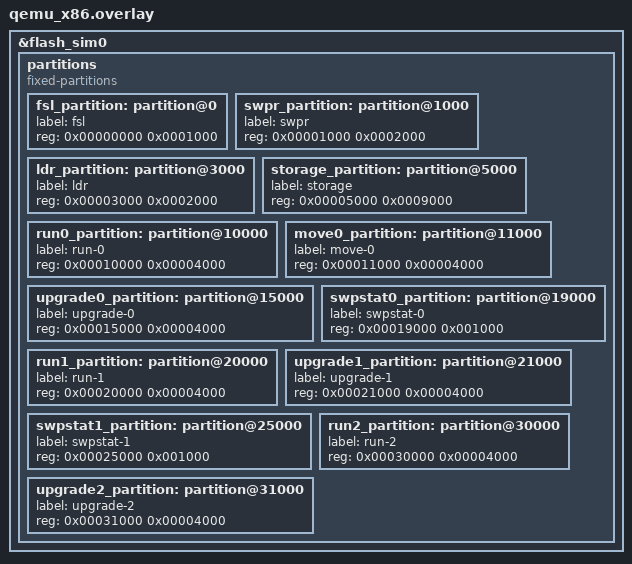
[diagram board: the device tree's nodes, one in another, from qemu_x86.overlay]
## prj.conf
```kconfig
CONFIG_ZTEST=y
CONFIG_ZTEST_STACKSIZE=8120
CONFIG_MAIN_STACK_SIZE=4096
CONFIG_FLASH=y
CONFIG_FLASH_PAGE_LAYOUT=y
#CONFIG_FLASH_SIMULATOR_DOUBLE_WRITES=y
CONFIG_FLASH_MAP=y
CONFIG_ZB_EIGHT=y
CONFIG_ZB_EIGHT_IS_SWAPPER=y

CONFIG_LOG=y
CONFIG_LOG_MINIMAL=y
```

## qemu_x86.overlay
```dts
/*
 * Copyright (c) 2019 Laczen
 *
 * SPDX-License-Identifier: Apache-2.0
 */

/delete-node/ &storage_partition;

&flash_sim0 {
	/*
	 * For more information, see:
	 * http://docs.zephyrproject.org/latest/guides/dts/index.html#flash-partitions
	 */
	partitions {
		compatible = "fixed-partitions";
		#address-cells = <1>;
		#size-cells = <1>;

		fsl_partition: partition@0 {
			label = "fsl";
			reg = <0x00000000 0x0001000>;
		};

		swpr_partition: partition@1000 {
			label = "swpr";
			reg = <0x00001000 0x0002000>;
		};

		ldr_partition: partition@3000 {
			label = "ldr";
			reg = <0x00003000 0x0002000>;
		};

		storage_partition: partition@5000 {
			label = "storage";
			reg = <0x00005000 0x0009000>;
		};

		run0_partition: partition@10000 {
			label = "run-0";
			reg = <0x00010000 0x00004000>;
		};
		move0_partition: partition@11000 {
			label = "move-0";
			reg = <0x00011000 0x00004000>;
		};
		upgrade0_partition: partition@15000 {
			label = "upgrade-0";
			reg = <0x00015000 0x00004000>;
		};
		swpstat0_partition: partition@19000 {
			label = "swpstat-0";
			reg = <0x00019000 0x001000>;
		};

		run1_partition: partition@20000 {
			label = "run-1";
			reg = <0x00020000 0x00004000>;
		};
		upgrade1_partition: partition@21000 {
			label = "upgrade-1";
			reg = <0x00021000 0x00004000>;
		};
		swpstat1_partition: partition@25000 {
			label = "swpstat-1";
			reg = <0x00025000 0x001000>;
		};

		run2_partition: partition@30000 {
			label = "run-2";
			reg = <0x00030000 0x00004000>;
		};
		upgrade2_partition: partition@31000 {
			label = "upgrade-2";
			reg = <0x00031000 0x00004000>;
		};
	};
};
```

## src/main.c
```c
/*
 * Copyright (c) 2017 Nordic Semiconductor ASA
 * Copyright (c) 2015 Runtime Inc
 *
 * SPDX-License-Identifier: Apache-2.0
 */

#include <logging/log.h>
LOG_MODULE_REGISTER(main);

extern void test_zb_flash(void);
extern void test_zb_tlv(void);
extern void test_zb_crypto(void);
extern void test_zb_image(void);
extern void test_zb_move(void);

void test_main(void)
{
	test_zb_flash();
	test_zb_tlv();
	test_zb_crypto();
	test_zb_image();
	test_zb_move();
}
```

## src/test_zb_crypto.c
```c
/*
 * Copyright (c) 2019 Laczen
 * Copyright (c) 2017 Nordic Semiconductor ASA
 * Copyright (c) 2015 Runtime Inc
 *
 * SPDX-License-Identifier: Apache-2.0
 */

#include <ztest.h>

#include <zb8/zb8_flash.h>
#include <zb8/zb8_crypto.h>

#include <logging/log.h>
LOG_MODULE_REGISTER(test_zb_crypto);

extern u8_t test_msg[];
extern u8_t test_msg_hash[];

/**
 * @brief Test hash calculation for data in flash
 */
void test_zb_hash(void)
{
	int err, cnt;
	struct zb_slt_info info;
	u8_t hash[HASH_BYTES];

	cnt = zb_slt_area_cnt();
	zassert_false(cnt == 0,  "Unable to get slotarea count: [cnt %d]", cnt);

	err = zb_slt_open(&info, cnt - 1, RUN);
	zassert_true(err == 0,  "Unable to get info: [err %d]", err);

	err = zb_erase(&info, 0, info.size);
	zassert_true(err == 0,  "Unable to erase image 0 area: [err %d]", err);

	err = zb_write(&info, 0, test_msg, HASH_BYTES);
	zassert_true(err == 0,  "Unable to write test message: [err %d]", err);


	err = zb_hash(hash, &info, 0, HASH_BYTES);
	zassert_true(err == 0, "Hash calculation failed: [err %d]", err);

	err = memcmp(hash, test_msg_hash, HASH_BYTES);
	zassert_true(err == 0, "Hash differs");
}

extern u8_t test_signature[];

/**
 * @brief Test signature verification
 */
void test_zb_sign_verify(void)
{
	int err;
	u8_t tmp;

	err = zb_sign_verify(test_msg_hash, test_signature);
	zassert_true(err == 0, "Signature validation failed: [err %d]", err);

	/* modify the key */
	tmp = test_msg_hash[0];
	test_msg_hash[0] >>=1;
	err = zb_sign_verify(test_msg_hash, test_signature);
	zassert_false(err == 0, "Invalid hash generates valid signature");

	/* reset the key */
	test_msg_hash[0] = tmp;

}

extern u8_t test_enc_pub_key[];
extern u8_t test_enc_key[];

/**
 * @brief Test the generation of an encryption key from public key
 */
void test_zb_get_encr_key(void)
{
	int err;
	u8_t enc_key[16], nonce[16], tmp;

	err = zb_get_encr_key(enc_key, nonce, test_enc_pub_key, 16);
	zassert_true(err == 0,  "Failed to get encryption key: [err %d]", err);
	err = memcmp(enc_key, test_enc_key, 16);
	zassert_true(err == 0,  "Encryption keys differ: [err %d]", err);

	/* modify the key */
	tmp = test_enc_pub_key[0];
	test_enc_pub_key[0] >>= 1;
	err = zb_get_encr_key(enc_key, nonce, test_enc_pub_key, 16);
	zassert_false(err == 0,  "Invalid pubkey generates encryption key");

	/* reset the key */
	test_enc_pub_key[0] = tmp;

}

extern u8_t test_msg[];
extern u8_t ec256_boot_pri_key[];
u8_t enc_test_msg[HASH_BYTES];
u8_t dec_test_msg[HASH_BYTES];

/**
 * @brief Test the aes enc routine
 */
void test_zb_aes_enc(void)
{
	int err;

	u8_t ctr[AES_BLOCK_SIZE]={0};

	memcpy(enc_test_msg, test_msg, HASH_BYTES);
	err = zb_aes_ctr_mode(enc_test_msg, HASH_BYTES, ctr,
			      ec256_boot_pri_key);
	zassert_true(err == 0,  "AES CTR returned [err %d]", err);
	err = ctr[15] - HASH_BYTES/AES_BLOCK_SIZE;
	zassert_true(err == 0,  "AES CTR wrong CTR value");
	err = memcmp(enc_test_msg, test_msg, HASH_BYTES);
	zassert_false(err == 0,  "AES wrong encrypt data");

}
void test_zb_aes_dec(void)
{
	int err;

	u8_t ctr[AES_BLOCK_SIZE]={0};

	memcpy(dec_test_msg, enc_test_msg, HASH_BYTES);
	err = zb_aes_ctr_mode(dec_test_msg, HASH_BYTES, ctr,
			      ec256_boot_pri_key);
	zassert_true(err == 0,  "AES CTR returned [err %d]", err);
	err = ctr[15] - HASH_BYTES/AES_BLOCK_SIZE;
	zassert_true(err == 0,  "AES CTR wrong CTR value");
	err = memcmp(dec_test_msg, test_msg, HASH_BYTES);
	zassert_true(err == 0,  "AES wrong decrypt data");

}

void test_zb_crypto(void)
{
	ztest_test_suite(test_zb_crypto,
			 ztest_unit_test(test_zb_aes_enc),
			 ztest_unit_test(test_zb_aes_dec),
			 ztest_unit_test(test_zb_hash),
			 ztest_unit_test(test_zb_sign_verify),
			 ztest_unit_test(test_zb_get_encr_key)
	);

	ztest_run_test_suite(test_zb_crypto);
}
```

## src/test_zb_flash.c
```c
/*
 * Copyright (c) 2019 Laczen
 * Copyright (c) 2017 Nordic Semiconductor ASA
 * Copyright (c) 2015 Runtime Inc
 *
 * SPDX-License-Identifier: Apache-2.0
 */

#include <ztest.h>

#include <zb8/zb8_flash.h>

#include <logging/log.h>
LOG_MODULE_REGISTER(test_zb_flash);

/**
 * @brief Test zb_slt_open()
 */
void test_zb_slt_open(void)
{
	int err, cnt;
	struct zb_slt_info slt_info;

	cnt = zb_slt_area_cnt();
	zassert_false(cnt == 0,  "Unable to get slotarea count: [cnt %d]", cnt);

	while (cnt > 0) {
		err = zb_slt_open(&slt_info, cnt - 1, RUN);
		zassert_true(err == 0, "Unable to open RUN: [err %d]", err);
		LOG_INF("RUN offset [%x], size [%d]", slt_info.offset,
			slt_info.size);

		err = zb_slt_open(&slt_info, cnt - 1, MOVE);
		zassert_true(err == 0, "Unable to open MOVE: [err %d]", err);
		LOG_INF("MOVE offset [%x], size [%d]", slt_info.offset,
			slt_info.size);

		err = zb_slt_open(&slt_info, cnt - 1, UPGRADE);
		zassert_true(err == 0, "Unable to open UPGRADE: [err %d]", err);
		LOG_INF("UPGRADE offset [%x], size [%d]", slt_info.offset,
			slt_info.size);

		err = zb_slt_open(&slt_info, cnt - 1, SWPSTAT);
		zassert_true(err == 0, "Unable to open SWPSTAT: [err %d]", err);
		LOG_INF("SWPSTAT offset [%x], size [%d]", slt_info.offset,
			slt_info.size);

		cnt--;
	}
}

/**
 * @brief Test zb_sectorsize_get()
 */
void test_zb_sectorsize_get(void)
{
	int cnt;
	uint32_t sectorsize;

	cnt = zb_slt_area_cnt();
	zassert_false(cnt == 0,  "Unable to get slotarea count: [cnt %d]", cnt);

	while (cnt > 0) {
		sectorsize = zb_sectorsize_get(cnt - 1);
		zassert_false(sectorsize == 0, "Sectorsize error");
		LOG_INF("Sectorsize [%d]", sectorsize);

		cnt--;
	}
}

/**
 * Helper routine for flash testing
 */
static void fltest(struct zb_slt_info *slt_info)
{
	int err;
	uint8_t buf[8] = {0x00, 0x01, 0x02, 0x03, 0x04, 0x05, 0x06, 0x07};
	uint8_t rdbuf[8];

	err = zb_erase(slt_info, 0, slt_info->size);
	zassert_true(err == 0, "Flash erase error [err %d]", err);
	err = zb_write(slt_info, 0, buf, sizeof(buf));
	zassert_true(err == 0, "Flash write error [err %d]", err);
	err = zb_read(slt_info, 0, rdbuf, sizeof(rdbuf));
	zassert_true(err == 0, "Flash read error [err %d]", err);
	err = memcmp(buf, rdbuf, sizeof(buf));
	zassert_true(err == 0, "Flash read error value differs");
	err = zb_erase(slt_info, 0, slt_info->size);
	zassert_true(err == 0, "Flash erase error [err %d]", err);
}

/**
 * @brief Test zb_erase/write/read
 */
void test_zb_ewr(void)
{
	int err, cnt;
	struct zb_slt_info slt_info;

	cnt = zb_slt_area_cnt();
	zassert_false(cnt == 0,  "Unable to get slotarea count: [cnt %d]", cnt);

	while (cnt > 0) {
		err = zb_slt_open(&slt_info, cnt - 1, RUN);
		zassert_true(err == 0, "Unable to open RUN: [err %d]", err);
		fltest(&slt_info);

		err = zb_slt_open(&slt_info, cnt - 1, MOVE);
		zassert_true(err == 0, "Unable to open MOVE: [err %d]", err);
		fltest(&slt_info);

		err = zb_slt_open(&slt_info, cnt - 1, UPGRADE);
		zassert_true(err == 0, "Unable to open UPGRADE: [err %d]", err);
		fltest(&slt_info);

		err = zb_slt_open(&slt_info, cnt - 1, SWPSTAT);
		zassert_true(err == 0, "Unable to open SWPSTAT: [err %d]", err);
		if (slt_info.size) {
			fltest(&slt_info);
		}

		cnt--;
	}
}

/**
 * @brief Test read and write of zb commands
 */
void test_zb_cmd(void)
{
	int err, cnt;
	struct zb_slt_info slt_info;
	struct zb_cmd cmd, cmd_rd;

	cnt = zb_slt_area_cnt();
	zassert_false(cnt == 0,  "Unable to get slotarea count: [cnt %d]", cnt);

	err = zb_slt_open(&slt_info, 0, SWPSTAT);
	zassert_true(err == 0,  "Unable to get slotarea info: [err %d]", err);

	err = zb_erase(&slt_info, 0, slt_info.size);
	zassert_true(err == 0,  "Unable to erase stat area: [err %d]", err);

	err = zb_cmd_read(&slt_info, &cmd_rd);
	zassert_true(err == -ENOENT, "Found cmd entry in empty flash area");

	cmd.cmd1 = 0x0;
	cmd.cmd2 = 0x0;
	cmd.cmd3 = 0x0;

	err = zb_cmd_write(&slt_info, &cmd);
	zassert_true(err == 0, "Failed to write command");

	err = zb_cmd_read(&slt_info, &cmd_rd);
	zassert_true(((cmd.cmd1 == cmd_rd.cmd1) && (cmd.cmd2 == cmd_rd.cmd2) &&
		     (cmd.cmd3 == cmd_rd.cmd3)),
		      "Found different cmd entry in flash area");

	/* write commands until stat area is full */
	while (err == 0) {
		cmd.cmd3++;
		err = zb_cmd_write(&slt_info, &cmd);
		if (cmd.cmd3 > 1024) {
			break;
		}
	}
	zassert_true(err == -ENOSPC, "To many cmd writes possible");
}

void test_zb_flash(void)
{
	ztest_test_suite(test_zb_flash,
			 ztest_unit_test(test_zb_slt_open),
			 ztest_unit_test(test_zb_sectorsize_get),
			 ztest_unit_test(test_zb_ewr),
			 ztest_unit_test(test_zb_cmd)
			);

	ztest_run_test_suite(test_zb_flash);

}
```

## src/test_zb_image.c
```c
/*
 * Copyright (c) 2019 Laczen
 * Copyright (c) 2017 Nordic Semiconductor ASA
 * Copyright (c) 2015 Runtime Inc
 *
 * SPDX-License-Identifier: Apache-2.0
 */

#include <ztest.h>

#include <zb8/zb8_flash.h>
#include <zb8/zb8_image.h>

#include <logging/log.h>
LOG_MODULE_REGISTER(test_zb_image);

extern const unsigned char test_image_pln[1536];
extern const unsigned char test_image1_enc[1536];

#define HDR_SIZE 512
#define IMG_SIZE 1024

/**
 * @brief Test the opening of a image in slot RUN
 */
void test_zb_open_image(void)
{
	int err;
	struct zb_slt_info slt_info;
	struct zb_img_info info;

	err = zb_slt_open(&slt_info, 0, RUN);
	zassert_true(err == 0,  "Unable to get slotarea info: [err %d]", err);

	err = zb_erase(&slt_info, 0, slt_info.size);
	zassert_true(err == 0,  "Unable to erase image 0 area: [err %d]", err);

	err = zb_write(&slt_info, 0, test_image_pln, sizeof(test_image_pln));
	zassert_true(err == 0,  "Unable to write the image: [err %d]", err);

	/* without any verification */
	err = zb_get_img_info(&info, &slt_info);
	zassert_true(err == 0,  "Error loading image info: [err %d]", err);
	err = info.start - HDR_SIZE;
	zassert_true(err == 0,  "Wrong img start");
	err = info.end - IMG_SIZE - HDR_SIZE;
	zassert_true(err == 0,  "Wrong img size");
	err = info.end - info.enc_start;
	zassert_true(err == 0,  "Wrong enc start");

	/* with all verification */
	err = zb_val_img_info(&info, &slt_info, &slt_info);
	zassert_true(err == 0,  "Error loading image info: [err %d]", err);
	err = info.start - HDR_SIZE;
	zassert_true(err == 0,  "Wrong img start");
	err = info.end - IMG_SIZE - HDR_SIZE;
	zassert_true(err == 0,  "Wrong img size");
	err = info.end - info.enc_start;
	zassert_true(err == 0,  "Wrong enc start");
}

void test_zb_open_image_enc(void)
{
	int err;
	struct zb_slt_info slt_info;
	struct zb_img_info info;

	err = zb_slt_open(&slt_info, 0, RUN);
	zassert_true(err == 0,  "Unable to get slotarea info: [err %d]", err);

	err = zb_erase(&slt_info, 0, slt_info.size);
	zassert_true(err == 0,  "Unable to erase image 0 area: [err %d]", err);

	err = zb_write(&slt_info, 0, test_image1_enc, sizeof(test_image1_enc));
	zassert_true(err == 0,  "Unable to write the image: [err %d]", err);

	/* without any verification */
	err = zb_get_img_info(&info, &slt_info);
	zassert_true(err == 0,  "Error loading image info: [err %d]", err);
	err = info.start - HDR_SIZE;
	zassert_true(err == 0,  "Wrong img start");
	err = info.end - IMG_SIZE - HDR_SIZE;
	zassert_true(err == 0,  "Wrong img size");
	err = info.start - info.enc_start;
	zassert_true(err == 0,  "Wrong enc start");

	/* with all verification */
	err = zb_val_img_info(&info, &slt_info, &slt_info);
	zassert_true(err == 0,  "Error loading image info: [err %d]", err);
	err = info.start - HDR_SIZE;
	zassert_true(err == 0,  "Wrong img start");
	err = info.end - IMG_SIZE - HDR_SIZE;
	zassert_true(err == 0,  "Wrong img size");
	err = info.start - info.enc_start;
	zassert_true(err == 0,  "Wrong enc start");
}

void test_zb_image(void)
{
	ztest_test_suite(test_zb_image,
			 ztest_unit_test(test_zb_open_image),
			 ztest_unit_test(test_zb_open_image_enc)
			);

	ztest_run_test_suite(test_zb_image);
}
```

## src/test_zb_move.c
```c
/*
 * Copyright (c) 2019 Laczen
 * Copyright (c) 2017 Nordic Semiconductor ASA
 * Copyright (c) 2015 Runtime Inc
 *
 * SPDX-License-Identifier: Apache-2.0
 */

#include <ztest.h>

#include <zb8/zb8_move.h>
#include <zb8/zb8_flash.h>
#include <zb8/zb8_image.h>

#include <logging/log.h>
LOG_MODULE_REGISTER(test_zb_move);

extern const unsigned char test_image_pln[1536];
extern const unsigned char test_image1_enc[1536];
extern const unsigned char test_image2_enc[1536];
extern const unsigned char test_imageboot_enc[1536];

#define HDR_SIZE 512
#define HDR_SKIP 32
#define IMG_SIZE 1024

void move_test(uint8_t sm_idx, const unsigned char *image)
{
	int err;
	struct zb_slt_info slt_info;
	u8_t imgheader[HDR_SIZE];
	u8_t img[IMG_SIZE];

	err = zb_slt_open(&slt_info, sm_idx, UPGRADE);
	zassert_true(err == 0,  "Unable to get slotarea info: [err %d]", err);

	err = zb_write(&slt_info, 0, image, HDR_SIZE + IMG_SIZE);
	zassert_true(err == 0,  "Unable to write the image: [err %d]", err);

	err = zb_slt_open(&slt_info, sm_idx, SWPSTAT);
	zassert_true(err == 0,  "Unable to get slotarea info: [err %d]", err);

	err = zb_erase(&slt_info, 0, slt_info.size);
	zassert_true(err == 0,  "Unable to erase SWPSTAT area: [err %d]", err);

	err = zb_img_swap(sm_idx);

	err = zb_slt_open(&slt_info, sm_idx, RUN);
	zassert_true(err == 0,  "Unable to get slotarea info: [err %d]", err);
	err = zb_read(&slt_info, 0, imgheader, HDR_SIZE - HDR_SKIP);
	zassert_true(err == 0, "Unable to read moved header");
	err = memcmp(&imgheader, image, HDR_SIZE - HDR_SKIP);
	zassert_true(err == 0, "Difference detected in moved header");

	err = zb_read(&slt_info, HDR_SIZE, img, IMG_SIZE);
	zassert_true(err == 0, "Unable to read moved image");
	err = memcmp(img, &test_image_pln[HDR_SIZE], IMG_SIZE);
	zassert_true(err == 0, "Difference detected in image");
}
/**
 * @brief Test the unencrypted move
 */
void test_zb_image_move_pln(void)
{
	int cnt, err;
	struct zb_slt_info slt_info;

	cnt = zb_slt_area_cnt();
	zassert_false(cnt == 0,  "Unable to get slotarea count: [cnt %d]", cnt);

	while ((cnt--) > 0) {
		LOG_INF("Testing Region %d", cnt);
		err = zb_slt_open(&slt_info, cnt, RUN);
		zassert_true(err == 0,  "Unable to get slotarea info: [err %d]",
			     err);
		err = zb_erase(&slt_info, 0U, slt_info.size);
		zassert_true(err == 0,  "Failed to erase RUN area");
		err = zb_slt_open(&slt_info, cnt, UPGRADE);
		zassert_true(err == 0,  "Unable to get slotarea info: [err %d]",
			     err);
		err = zb_erase(&slt_info, 0U, slt_info.size);
		zassert_true(err == 0,  "Failed to erase UPGRADE area");
		move_test(cnt, test_image_pln);
	}
}

/**
 * @brief Test the encrypted move
 */
void test_zb_image_move_enc(void)
{
	int cnt, err;
	struct zb_slt_info slt_info;

	cnt = zb_slt_area_cnt();
	zassert_false(cnt == 0,  "Unable to get slotarea count: [cnt %d]", cnt);

	while ((cnt--) > 0) {
		LOG_INF("Testing Region %d", cnt);
		err = zb_slt_open(&slt_info, cnt, RUN);
		zassert_true(err == 0,  "Unable to get slotarea info: [err %d]",
			     err);
		err = zb_erase(&slt_info, 0U, slt_info.size);
		zassert_true(err == 0,  "Failed to erase RUN area");
		err = zb_slt_open(&slt_info, cnt, UPGRADE);
		zassert_true(err == 0,  "Unable to get slotarea info: [err %d]",
			     err);
		err = zb_erase(&slt_info, 0U, slt_info.size);
		zassert_true(err == 0,  "Failed to erase UPGRADE area");
		move_test(cnt, test_image1_enc);
	}
}

/**
 * @brief Test a pattern of uploads
 */
void test_zb_image_pattern_0(void)
{
	int cnt, err;
	struct zb_slt_info slt_info;
	u8_t imgheader[HDR_SIZE];

	cnt = 0;
	LOG_INF("Testing Region %d", cnt);
	err = zb_slt_open(&slt_info, cnt, RUN);
	zassert_true(err == 0,  "Unable to get slotarea info: [err %d]", err);
	err = zb_erase(&slt_info, 0U, slt_info.size);
	zassert_true(err == 0,  "Failed to erase RUN area");

	/* Put test_image1_enc */
	LOG_INF("Starting placement of test_image1_enc");
	err = zb_slt_open(&slt_info, cnt, UPGRADE);
	zassert_true(err == 0,  "Unable to get slotarea info: [err %d]", err);
	err = zb_erase(&slt_info, 0U, slt_info.size);
	zassert_true(err == 0,  "Failed to erase UPGRADE area");
	err = zb_write(&slt_info, 0, test_image1_enc, HDR_SIZE + IMG_SIZE);
	zassert_true(err == 0,  "Unable to write image: [err %d]", err);

	err = zb_slt_open(&slt_info, cnt, SWPSTAT);
	zassert_true(err == 0,  "Unable to get slotarea info: [err %d]", err);
	err = zb_erase(&slt_info, 0, slt_info.size);
	zassert_true(err == 0,  "Unable to erase SWPSTAT area: [err %d]", err);

	err = zb_img_swap(cnt);
	zassert_true(err == 0,  "SWAP returned error: [err %d]", err);

	err = zb_slt_open(&slt_info, cnt, RUN);
	zassert_true(err == 0,  "Unable to get slotarea info: [err %d]", err);
	err = zb_read(&slt_info, 0, imgheader, HDR_SIZE);
	zassert_true(err == 0, "Unable to read moved header");
	err = memcmp(&imgheader[HDR_SKIP], &test_image1_enc[HDR_SKIP],
		     HDR_SIZE-HDR_SKIP);
	zassert_true(err == 0, "Difference detected in moved header");

	/* Put test_image2_enc */
	LOG_INF("Starting upgrade to test_image2_enc");
	err = zb_slt_open(&slt_info, cnt, UPGRADE);
	zassert_true(err == 0,  "Unable to get slotarea info: [err %d]", err);
	err = zb_erase(&slt_info, 0U, slt_info.size);
	zassert_true(err == 0,  "Failed to erase UPGRADE area");
	err = zb_write(&slt_info, 0, test_image2_enc, HDR_SIZE + IMG_SIZE);
	zassert_true(err == 0,  "Unable to write image: [err %d]", err);

	err = zb_slt_open(&slt_info, cnt, SWPSTAT);
	zassert_true(err == 0,  "Unable to get slotarea info: [err %d]", err);
	err = zb_erase(&slt_info, 0, slt_info.size);
	zassert_true(err == 0,  "Unable to erase SWPSTAT area: [err %d]", err);

	err = zb_img_swap(cnt);
	zassert_true(err == 0,  "SWAP returned error: [err %d]", err);

	err = zb_slt_open(&slt_info, cnt, RUN);
	zassert_true(err == 0,  "Unable to get slotarea info: [err %d]", err);
	err = zb_read(&slt_info, 0, imgheader, HDR_SIZE);
	zassert_true(err == 0, "Unable to read moved header");
	err = memcmp(&imgheader[HDR_SKIP], &test_image2_enc[HDR_SKIP],
		     HDR_SIZE-HDR_SKIP);
	zassert_true(err == 0, "Difference detected in moved header");

	/* call swap again, this should restore test_image1_enc */
	LOG_INF("Starting restore of test_image1_enc");
	err = zb_img_swap(cnt);
	zassert_true(err == 0,  "SWAP returned error: [err %d]", err);

	err = zb_slt_open(&slt_info, cnt, RUN);
	zassert_true(err == 0,  "Unable to get slotarea info: [err %d]", err);
	err = zb_read(&slt_info, 0, imgheader, HDR_SIZE);
	zassert_true(err == 0, "Unable to read moved header");
	err = memcmp(&imgheader[HDR_SKIP], &test_image1_enc[HDR_SKIP],
		     HDR_SIZE-HDR_SKIP);
	zassert_true(err == 0, "Difference detected in moved header");

	/* Put test_imageboot_enc a bootloader - do not erase the swpstat */
	LOG_INF("Starting upgrade of bootloader");
	err = zb_slt_open(&slt_info, cnt, UPGRADE);
	zassert_true(err == 0,  "Unable to get slotarea info: [err %d]", err);
	err = zb_erase(&slt_info, 0U, slt_info.size);
	zassert_true(err == 0,  "Failed to erase UPGRADE area");
	err = zb_write(&slt_info, 0, test_imageboot_enc, HDR_SIZE + IMG_SIZE);
	zassert_true(err == 0,  "Unable to write image: [err %d]", err);

	err = zb_img_swap(cnt);
	zassert_true(err == 0,  "SWAP returned error: [err %d]", err);

	err = zb_slt_open(&slt_info, cnt, RUN);
	zassert_true(err == 0,  "Unable to get slotarea info: [err %d]", err);
	err = zb_read(&slt_info, 0, imgheader, HDR_SIZE);
	zassert_true(err == 0, "Unable to read moved header");
	err = memcmp(&imgheader[HDR_SKIP], &test_imageboot_enc[HDR_SKIP],
		     HDR_SIZE-HDR_SKIP);
	zassert_true(err == 0, "Difference detected in moved header");

	/* Call swap again, should restore the previous image */
	LOG_INF("Restore test_image1_enc after bootloader");
	err = zb_img_swap(cnt);
	zassert_true(err == 0,  "SWAP returned error: [err %d]", err);

	err = zb_slt_open(&slt_info, cnt, RUN);
	zassert_true(err == 0,  "Unable to get slotarea info: [err %d]", err);
	err = zb_read(&slt_info, 0, imgheader, HDR_SIZE);
	zassert_true(err == 0, "Unable to read moved header");
	err = memcmp(&imgheader[HDR_SKIP], &test_image1_enc[HDR_SKIP],
		     HDR_SIZE-HDR_SKIP);
	zassert_true(err == 0, "Difference detected in moved header");

	/* Upgrade to test_image2_enc */
	LOG_INF("Upgrade to test_image2_enc");
	err = zb_slt_open(&slt_info, cnt, UPGRADE);
	zassert_true(err == 0,  "Unable to get slotarea info: [err %d]", err);
	err = zb_erase(&slt_info, 0U, slt_info.size);
	zassert_true(err == 0,  "Failed to erase UPGRADE area");
	err = zb_write(&slt_info, 0, test_image2_enc, HDR_SIZE + IMG_SIZE);
	zassert_true(err == 0,  "Unable to write image: [err %d]", err);
	err = zb_slt_open(&slt_info, cnt, SWPSTAT);
	zassert_true(err == 0,  "Unable to get slotarea info: [err %d]", err);
	err = zb_erase(&slt_info, 0, slt_info.size);
	zassert_true(err == 0,  "Unable to erase SWPSTAT area: [err %d]", err);

	err = zb_img_swap(cnt);
	zassert_true(err == 0,  "SWAP returned error: [err %d]", err);

	err = zb_slt_open(&slt_info, cnt, RUN);
	zassert_true(err == 0,  "Unable to get slotarea info: [err %d]", err);
	err = zb_read(&slt_info, 0, imgheader, HDR_SIZE);
	zassert_true(err == 0, "Unable to read moved header");
	err = memcmp(&imgheader[HDR_SKIP], &test_image2_enc[HDR_SKIP],
		     HDR_SIZE-HDR_SKIP);
	zassert_true(err == 0, "Difference detected in moved header");

	/* Confirm the image */
	//LOG_INF("Confirming test_image2_enc");
	//err = zb_fsl_hdr_confirm(slt_info.fl_dev, slt_info.offset);

	/* Try to restore the previous image */
	LOG_INF("Try to restore previous image, should do nothing");
	err = zb_slt_open(&slt_info, cnt, SWPSTAT);
	zassert_true(err == 0,  "Unable to get slotarea info: [err %d]", err);
	err = zb_erase(&slt_info, 0, slt_info.size);
	zassert_true(err == 0,  "Unable to erase SWPSTAT area: [err %d]", err);

	err = zb_img_swap(cnt);
	zassert_true(err == 0,  "SWAP returned error: [err %d]", err);

	err = zb_slt_open(&slt_info, cnt, RUN);
	zassert_true(err == 0,  "Unable to get slotarea info: [err %d]", err);
	err = zb_read(&slt_info, 0, imgheader, HDR_SIZE);
	zassert_true(err == 0, "Unable to read moved header");
	// err = memcmp(&imgheader[HDR_SKIP], &test_image1_enc[HDR_SKIP],
	// 	     HDR_SIZE-HDR_SKIP);
	// zassert_false(err == 0, "Header is equal to test_image1_enc header");

}

void test_zb_move(void)
{
	ztest_test_suite(test_zb_move,
			 ztest_unit_test(test_zb_image_move_pln),
			 ztest_unit_test(test_zb_image_move_enc),
			 ztest_unit_test(test_zb_image_pattern_0)
			);

	ztest_run_test_suite(test_zb_move);
}
```

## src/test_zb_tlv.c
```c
/*
 * Copyright (c) 2019 Laczen
 * Copyright (c) 2017 Nordic Semiconductor ASA
 * Copyright (c) 2015 Runtime Inc
 *
 * SPDX-License-Identifier: Apache-2.0
 */

#include <ztest.h>

#include <zb8/zb8_tlv.h>

#include <logging/log.h>
LOG_MODULE_REGISTER(test_zb_tlv);

extern u8_t test_msg[];
extern u8_t test_signature[];

#define HAYSTACK_BYTES 32
uint8_t test_haystack[HAYSTACK_BYTES] = {
	1,0,2,0, 1,2, 	/* type = 1, length = 2, value = 1 2 */
	2,0,3,0, 3,4,5, /* type = 2, length = 3, value = 3 4 5 */
	3,0,1,0, 6,	/* type = 3, length = 1, value = 6 */
	0,1,2,0, 7,8,	/* type = 0x10, length = 1, value = 7 8 */
	0,0		/* end the tlv area with a type zero */
};

/**
 * @brief Test tlv_step method to step through a haystack in ram
 */
void test_zb_tlv_step(void)
{
	int err;
	struct tlv_entry entry;
	u32_t offset;

	offset = 0;
	entry.type = 0;
	while ((!zb_step_tlv(test_haystack, &offset, &entry)) &&
	       (entry.type != 1));
	zassert_true(entry.type == 1, "Entry type 1 not found");
	err = memcmp(&test_haystack[4], entry.value, entry.length);
	zassert_true(err == 0, "Entry type 1 wrong value");

	offset = 0;
	entry.type = 0;
	while ((!zb_step_tlv(test_haystack, &offset, &entry)) &&
	       (entry.type != 2));
	zassert_true(entry.type == 2, "Entry type 2 not found");
	err = memcmp(&test_haystack[10], entry.value, entry.length);
	zassert_true(err == 0, "Entry type 2 wrong value");

	offset = 0;
	entry.type = 0;
	while ((!zb_step_tlv(test_haystack, &offset, &entry)) &&
	       (entry.type != 3));
	zassert_true(entry.type == 3, "Entry type 3 not found");
	err = memcmp(&test_haystack[17], entry.value, entry.length);
	zassert_true(err == 0, "Entry type 3 wrong value");

	offset = 0;
	entry.type = 0;
	while ((!zb_step_tlv(test_haystack, &offset, &entry)) &&
	       (entry.type != 0x100));
	zassert_true(entry.type == 0x100, "Entry type 0x100 not found");
	err = memcmp(&test_haystack[22], entry.value, entry.length);
	zassert_true(err == 0, "Entry type 0x100 wrong value");

	/* Look for non-existing entry */
	offset = 0;
	entry.type = 0;
	while ((!zb_step_tlv(test_haystack, &offset, &entry)) &&
	       (entry.type != 5));
	zassert_false(entry.type == 5, "Found non-existing entry");

}

void test_zb_tlv(void)
{
	ztest_test_suite(test_zb_tlv,
			 ztest_unit_test(test_zb_tlv_step)
			);

	ztest_run_test_suite(test_zb_tlv);
}
```

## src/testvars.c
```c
/*
 * Copyright (c) 2018 Laczen: Set of keys to test signing and encryption
 * key exchange.
 *
 * Keys definition: the bootloader has two types of keys:
 * a. A private encryption key that is used to derive the encryption key
 * b. A set of root public keys that is used to validate images
 *
 * SPDX-License-Identifier: Apache-2.0
 */

#include <zb8/zb8_crypto.h>

u8_t test_msg[HASH_BYTES] = {
	0xff, 0xfe, 0xfd, 0xfc, 0xfb, 0xfa, 0xf9, 0xf8,
	0xf7, 0xf6, 0xf5, 0xf4, 0xf3, 0xf2, 0xf1, 0xf0,
	0xff, 0xfe, 0xfd, 0xfc, 0xfb, 0xfa, 0xf9, 0xf8,
	0xf7, 0xf6, 0xf5, 0xf4, 0xf3, 0xf2, 0xf1, 0xf0
};


u8_t test_msg_hash[HASH_BYTES] = {
	87, 43, 26, 198, 187, 148, 71, 79,
	220, 38, 223, 89, 4, 118, 115, 109,
	231, 185, 12, 231, 123, 212, 221, 103,
	117, 243, 241, 37, 134, 175, 136, 251
};

u32_t test_msg_crc32 = 0x4D299FC3;

u8_t test_signature[SIGNATURE_BYTES] = {
	252, 86, 17, 53, 85, 142, 204, 211,
	55, 184, 117, 91, 159, 134, 6, 189,
	152, 48, 212, 168, 153, 194, 37, 69,
	159, 214, 44, 58, 39, 64, 19, 36,
	175, 12, 24, 179, 83, 243, 204, 68,
	125, 110, 101, 58, 175, 226, 88, 44,
	44, 100, 215, 166, 176, 109, 107, 238,
	238, 129, 253, 12, 66, 182, 43, 27
};

u8_t test_enc_pub_key[PUBLIC_KEY_BYTES] = {
	162, 232, 188, 223, 146, 244, 15, 182,
	171, 144, 101, 158, 237, 57, 205, 66,
	164, 144, 209, 239, 44, 138, 85, 163,
	97, 222, 197, 80, 96, 83, 34, 117,
	201, 36, 44, 25, 158, 7, 5, 165,
	73, 27, 116, 124, 239, 11, 239, 8,
	54, 48, 235, 178, 121, 206, 207, 21,
	192, 36, 184, 152, 219, 62, 106, 175
};

u8_t test_enc_key[16] = {
	100, 94, 130, 145, 92, 49, 78, 162,
	75, 150, 19, 98, 20, 112, 197, 170
};
```

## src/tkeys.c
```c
/*
 * Copyright (c) 2018 Laczen
 *
 * Keys definition: the bootloader has two types of keys:
 * a. A private encryption key that is used to derive the encryption key
 * b. A set of root public keys that is used to validate images
 *
 * SPDX-License-Identifier: Apache-2.0
 */

#include <zephyr.h>

const u8_t ec256_boot_pri_key[] = {
	0xf6, 0x96, 0xe9, 0x4f, 0xa5, 0x5d, 0xd1, 0xda,
	0x2b, 0x77, 0x44, 0x8d, 0x5b, 0x0a, 0x25, 0x3d,
	0x6b, 0x12, 0x59, 0xe9, 0x7f, 0x9f, 0x75, 0x18,
	0x9c, 0xa3, 0xbd, 0x2c, 0x3a, 0x17, 0x5d, 0x83,
};

const u16_t ec256_boot_pri_key_len = 32;

const u8_t ec256_root_pub_key[] = {
	/* First part is a bad key */
	0x1e, 0x8d, 0xef, 0xb8, 0x12, 0xf7, 0x2d, 0x71,
	0x2f, 0xdf, 0xc5, 0xa5, 0x2c, 0x08, 0x5d, 0xc8,
	0xd5, 0x7d, 0x8f, 0x5b, 0xa9, 0xa4, 0x93, 0xf3,
	0xe7, 0x9e, 0x37, 0x98, 0xef, 0xf8, 0xbd, 0x41,
	0x37, 0x94, 0x32, 0x79, 0xea, 0x3b, 0xdc, 0xd4,
	0x9a, 0xc9, 0xb0, 0x98, 0x06, 0x33, 0xee, 0x83,
	0xfd, 0x24, 0x81, 0xfe, 0x09, 0xfa, 0xd3, 0xde,
	0xda, 0xc0, 0x13, 0xd0, 0xad, 0x2b, 0x15, 0x1d,
	/* This is a good key for test_image
	 * but bad for test signature */
	0x2e, 0x8d, 0xef, 0xb8, 0x12, 0xf7, 0x2d, 0x71,
	0x2f, 0xdf, 0xc5, 0xa5, 0x2c, 0x08, 0x5d, 0xc8,
	0xd5, 0x7d, 0x8f, 0x5b, 0xa9, 0xa4, 0x93, 0xf3,
	0xe7, 0x9e, 0x37, 0x98, 0xef, 0xf8, 0xbd, 0x41,
	0x37, 0x94, 0x32, 0x79, 0xea, 0x3b, 0xdc, 0xd4,
	0x9a, 0xc9, 0xb0, 0x98, 0x06, 0x33, 0xee, 0x83,
	0xfd, 0x24, 0x81, 0xfe, 0x09, 0xfa, 0xd3, 0xde,
	0xda, 0xc0, 0x13, 0xd0, 0xad, 0x2b, 0x15, 0x1d,
	/* This is a good key and test_signature
	 * but bad for test_image */
	0xac, 0x4b, 0xea, 0x21, 0xbf, 0xb6, 0x2f, 0xfc,
	0x1b, 0x89, 0xb6, 0xd5, 0x98, 0x67, 0xcd, 0x56,
	0x78, 0x28, 0x22, 0x55, 0xff, 0x39, 0xc2, 0xbb,
	0x93, 0xf8, 0xd1, 0x0b, 0x19, 0xf0, 0x81, 0x88,
	0x72, 0x82, 0x94, 0x22, 0xff, 0x66, 0x67, 0xa7,
	0xf3, 0xe9, 0x28, 0x60, 0x54, 0x96, 0x66, 0xa1,
	0xea, 0xb8, 0xb2, 0x9e, 0x5c, 0x66, 0xc4, 0x02,
	0x90, 0xd9, 0x95, 0xad, 0x97, 0x77, 0x02, 0x2f
};

const u16_t ec256_root_pub_key_len = 192;
```
